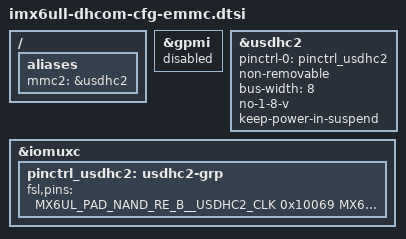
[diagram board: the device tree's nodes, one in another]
// SPDX-License-Identifier: (GPL-2.0-or-later)
/*
 * Copyright (C) 2018 DH electronics GmbH
 */

/*
 * Special configuration: emmc
 *
 * Enabled:  eMMC (on module)
 * Disabled: NAND (on module)
 */

/ {
	aliases {
		mmc2 = &usdhc2; /* eMMC (on module) should be mmc2 */
	};
};

&gpmi { /* NAND (on module) */
	status = "disabled";
};

&usdhc2 { /* eMMC (on module) */
	pinctrl-names = "default";
	pinctrl-0 = <&pinctrl_usdhc2>;
	non-removable;
	bus-width = <8>;
	no-1-8-v;
	keep-power-in-suspend;
	status = "okay";
};

&iomuxc {
	pinctrl_usdhc2: usdhc2-grp {
		fsl,pins = <
			MX6UL_PAD_NAND_RE_B__USDHC2_CLK		0x10069
			MX6UL_PAD_NAND_WE_B__USDHC2_CMD		0x17059
			MX6UL_PAD_NAND_DATA00__USDHC2_DATA0	0x17059
			MX6UL_PAD_NAND_DATA01__USDHC2_DATA1	0x17059
			MX6UL_PAD_NAND_DATA02__USDHC2_DATA2	0x17059
			MX6UL_PAD_NAND_DATA03__USDHC2_DATA3	0x17059
			MX6UL_PAD_NAND_DATA04__USDHC2_DATA4	0x17059
			MX6UL_PAD_NAND_DATA05__USDHC2_DATA5	0x17059
			MX6UL_PAD_NAND_DATA06__USDHC2_DATA6	0x17059
			MX6UL_PAD_NAND_DATA07__USDHC2_DATA7	0x17059
			MX6UL_PAD_NAND_ALE__USDHC2_RESET_B	0x17059 /* SD2 RESET */
		>;
	};
};
